# STM32C591xx register map
File version: 1.0
Registers are 32-bit, read-write, reset 0x0 unless marked. A register's access mark holds for its fields unless they carry their own. Offsets are from the block's base; [hi:lo] are bit positions; {n}, {i} and the like mark numbered series.

## TIM2 — TIM Address block
Base 0x40000000
Same registers: TIM3 0x40000400, TIM4 0x40000800, TIM5 0x40000C00
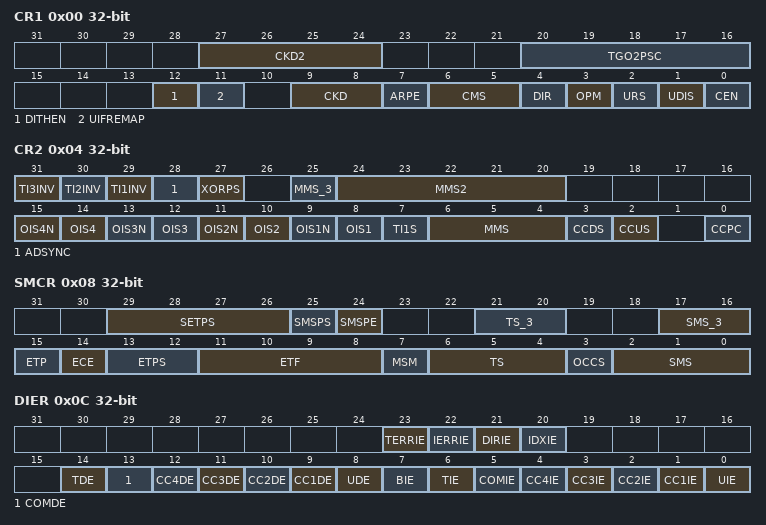
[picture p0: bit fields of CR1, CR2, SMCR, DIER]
0x00 CR1 — TIM control register 1
  [27:24] CKD2 — CKD2[3:0] bits (Clock division 2)
  [20:16] TGO2PSC — TGO2PSC[4:0] bits (Trigger output 2 postscaler)
  [12] DITHEN — DITHEN (Dithering enable)
  [11] UIFREMAP — UIFREMAP (UIF status bit remapping)
  [9:8] CKD — CKD[1:0] bits (Clock division)
  [7] ARPE — ARPE (Auto-reload preload enable)
  [6:5] CMS — CMS[1:0] bits (Center-aligned mode selection)
  [4] DIR — DIR (Direction)
  [3] OPM — OPM (One-pulse mode)
  [2] URS — URS (Update request source)
  [1] UDIS — UDIS (Update disable)
  [0] CEN — CEN (Counter enable)
0x04 CR2 — TIM control register 2
  [31] TI3INV — TI3INV (tim_ti{1} signal inversion on XOR gate input)
  [30] TI2INV — TI2INV (tim_ti{1} signal inversion on XOR gate input)
  [29] TI1INV — TI1INV (tim_ti{1} signal inversion on XOR gate input)
  [28] ADSYNC — ADSYNC (ADC synchronization)
  [27] XORPS — XORPS (XOR gate position selection)
  [25] MMS_3 — MMS[2:0] bits (Master mode selection)
  [24:20] MMS2 — MMS2[4:0] bits (Master mode selection 2)
  [2n+7] OIS{n}N (n=1..4) — OIS{n}N (Output idle state {n} (tim_oc{n}n output))
  [2n+6] OIS{n} (n=1..4) — OIS{n} (Output idle state {n} (tim_oc{n} output))
  [7] TI1S — TI1S (tim_ti1 selection)
  [6:4] MMS — MMS[2:0] bits (Master mode selection)
  [3] CCDS — CCDS (Capture/compare DMA selection)
  [2] CCUS — CCUS (Capture/compare control update selection)
  [0] CCPC — CCPC (Capture/compare preloaded control)
0x08 SMCR — TIM slave mode control register
  [29:26] SETPS — SETPS[3:0] bits (Synchronous External Trigger Prescaler)
  [25] SMSPS — SMSPS (SMS preload source)
  [24] SMSPE — SMSPE (SMS preload enable)
  [21:20] TS_3 — TS[2:0] bits (Trigger selection)
  [17:16] SMS_3 — SMS[2:0] bits (Slave mode selection)
  [15] ETP — ETP (External trigger polarity)
  [14] ECE — ECE (External clock enable)
  [13:12] ETPS — ETPS[1:0] bits (External trigger prescaler)
  [11:8] ETF — ETF[3:0] bits (External trigger filter)
  [7] MSM — MSM (Master/slave mode)
  [6:4] TS — TS[2:0] bits (Trigger selection)
  [3] OCCS — OCCS (OCREF clear selection)
  [2:0] SMS — SMS[2:0] bits (Slave mode selection)
0x0C DIER — TIM DMA/interrupt enable register
  [23] TERRIE — TERRIE (Transition error interrupt enable)
  [22] IERRIE — IERRIE (Index error interrupt enable)
  [21] DIRIE — DIRIE (Direction change interrupt enable)
  [20] IDXIE — IDXIE (Index interrupt enable)
  [14] TDE — TDE (Trigger DMA request enable)
  [13] COMDE — COMDE (COM DMA request enable)
  [n+8] CC{n}DE (n=1..4) — CC{n}DE (Capture/compare {n} DMA request enable)
  [8] UDE — UDE (Update DMA request enable)
  [7] BIE — BIE (Break interrupt enable)
  [6] TIE — TIE (Trigger interrupt enable)
  [5] COMIE — COMIE (COM interrupt enable)
  [n] CC{n}IE (n=1..4) — CC{n}IE (Capture/compare {n} interrupt enable)
  [0] UIE — UIE (Update interrupt enable)
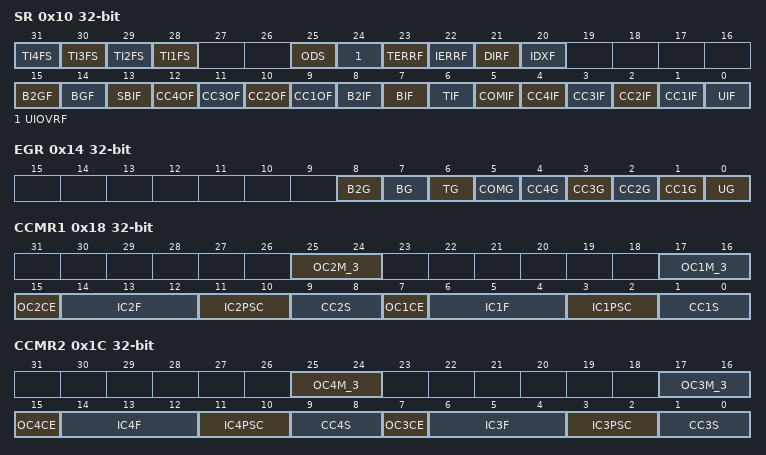
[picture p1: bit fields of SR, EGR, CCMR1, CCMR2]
0x10 SR — TIM status register
  [n+27] TI{n}FS (n=1..4) — TI{n}FS (tim_in{n}f status)
  [25] ODS — ODS (Output disable status)
  [24] UIOVRF — UIOVRF (Update Interrupt Overrun flag)
  [23] TERRF — TERRF (Transition error interrupt flag)
  [22] IERRF — IERRF (Index error interrupt flag)
  [21] DIRF — DIRF (Direction change interrupt flag)
  [20] IDXF — IDXF (Index interrupt flag)
  [15] B2GF — B2GF (Break 2 generation flag)
  [14] BGF — BGF (Break generation flag)
  [13] SBIF — SBIF (System break interrupt flag)
  [n+8] CC{n}OF (n=1..4) — CC{n}OF (Capture/compare {n} overcapture flag)
  [8] B2IF — B2IF (Break 2 interrupt flag)
  [7] BIF — BIF (Break interrupt flag)
  [6] TIF — TIF (Trigger interrupt flag)
  [5] COMIF — COMIF (COM interrupt flag)
  [n] CC{n}IF (n=1..4) — CC{n}IF (Capture/compare {n} interrupt flag)
  [0] UIF — UIF (Update interrupt flag)
0x14 EGR — TIM event generation register
  [8] B2G — B2G (Break 2 generation)
  [7] BG — BG (Break generation)
  [6] TG — TG (Trigger generation)
  [5] COMG — COMG (Capture/compare control update generation)
  [n] CC{n}G (n=1..4) — CC{n}G (Capture/compare {n} generation)
  [0] UG — UG (Update generation)
0x18 CCMR1 — TIM capture/compare mode register 1 [alternate]
  [25:24] OC2M_3 — OC2M[2:0] bits (Output compare 2 mode)
  [17:16] OC1M_3 — OC1M[2:0] bits (Output compare 1 mode)
  [15] OC2CE — OC2CE (Output compare 2 clear enable)
  [14:12] IC2F — IC2F[3:0] bits (Input capture 2 filter)
  [11:10] IC2PSC — IC2PSC[1:0] bits (Input capture 2 prescaler)
  [9:8] CC2S — CC2S[1:0] bits (Capture/compare 2 selection)
  [7] OC1CE — OC1CE (Output compare 1 clear enable)
  [6:4] IC1F — IC1F[3:0] bits (Input capture 1 filter)
  [3:2] IC1PSC — IC1PSC[1:0] bits (Input capture 1 prescaler)
  [1:0] CC1S — CC1S[1:0] bits (Capture/compare 1 selection)
0x1C CCMR2 — TIM capture/compare mode register 2 [alternate]
  [25:24] OC4M_3 — OC4M[2:0] bits (Output compare 4 mode)
  [17:16] OC3M_3 — OC3M[2:0] bits (Output compare 3 mode)
  [15] OC4CE — OC4CE (Output compare 4 clear enable)
  [14:12] IC4F — IC4F[3:0] bits (Input capture 4 filter)
  [11:10] IC4PSC — IC4PSC[1:0] bits (Input capture 4 prescaler)
  [9:8] CC4S — CC4S[1:0] bits (Capture/compare 4 selection)
  [7] OC3CE — OC3CE (Output compare 3 clear enable)
  [6:4] IC3F — IC3F[3:0] bits (Input capture 3 filter)
  [3:2] IC3PSC — IC3PSC[1:0] bits (Input capture 3 prescaler)
  [1:0] CC3S — CC3S[1:0] bits (Capture/compare 3 selection)
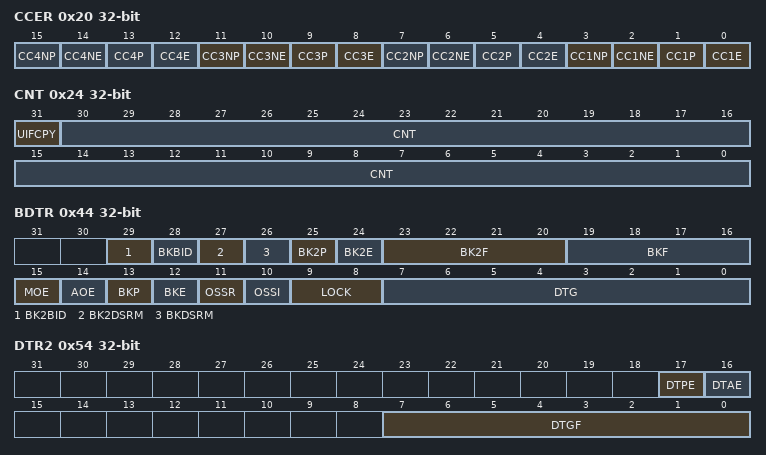
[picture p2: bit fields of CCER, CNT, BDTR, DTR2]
0x20 CCER — TIM capture/compare enable register
  [4n-1] CC{n}NP (n=1..4) — CC{n}NP (Capture/compare {n} complementary output polarity)
  [4n-2] CC{n}NE (n=1..4) — CC{n}NE (Capture/compare {n} complementary output enable)
  [4n-3] CC{n}P (n=1..4) — CC{n}P (Capture/compare {n} output polarity)
  [4n-4] CC{n}E (n=1..4) — CC{n}E (Capture/compare {n} output enable)
0x24 CNT — TIM counter
  [31] UIFCPY — UIFCPY (UIF copy)
  [30:0] CNT — CNT[30:0] bits (Counter value)
0x28 PSC — TIM prescaler
  [15:0] PSC — PSC[15:0] bits (Prescaler value)
0x2C ARR — TIM autoreload register
  [31:0] ARR — ARR[31:0] bits (Auto-reload value)
0x30 RCR — TIM repetition counter register
  [15:0] REP — REP[15:0] bits (Repetition counter reload value)
{0x30+4i} CCR{i} (i=1..3) — TIM capture/compare register {i}
  [31:0] CCR{i} — CCR{i}[31:0] bits (Capture/compare {i} value)
0x40 CCR4 — TIM capture/compare register 4
  [31:0] CCR4 — CCR4[19:0] bits (Capture/compare 4 value)
0x44 BDTR — TIM break and dead-time register
  [29] BK2BID — BK2BID (Break2 bidirectional)
  [28] BKBID — BKBID (Break bidirectional)
  [27] BK2DSRM — BK2DSRM (Break2 disarm)
  [26] BKDSRM — BKDSRM (Break disarm)
  [25] BK2P — BK2P (Break 2 polarity)
  [24] BK2E — BK2E (Break 2 enable)
  [23:20] BK2F — BK2F[3:0] bits (Break 2 filter)
  [19:16] BKF — BKF[3:0] bits (Break filter)
  [15] MOE — MOE (Main output enable)
  [14] AOE — AOE (Automatic output enable)
  [13] BKP — BKP (Break polarity)
  [12] BKE — BKE (Break enable)
  [11] OSSR — OSSR (Off-state selection for Run mode)
  [10] OSSI — OSSI (Off-state selection for idle mode)
  [9:8] LOCK — LOCK[1:0] bits (Lock configuration)
  [7:0] DTG — DTG[7:0] bits (Dead-time generator setup)
0x54 DTR2 — TIM timer deadtime register 2
  [17] DTPE — DTPE (Deadtime preload enable)
  [16] DTAE — DTAE (Deadtime asymmetric enable)
  [7:0] DTGF — DTGF[7:0] bits (Dead-time falling edge generator setup)
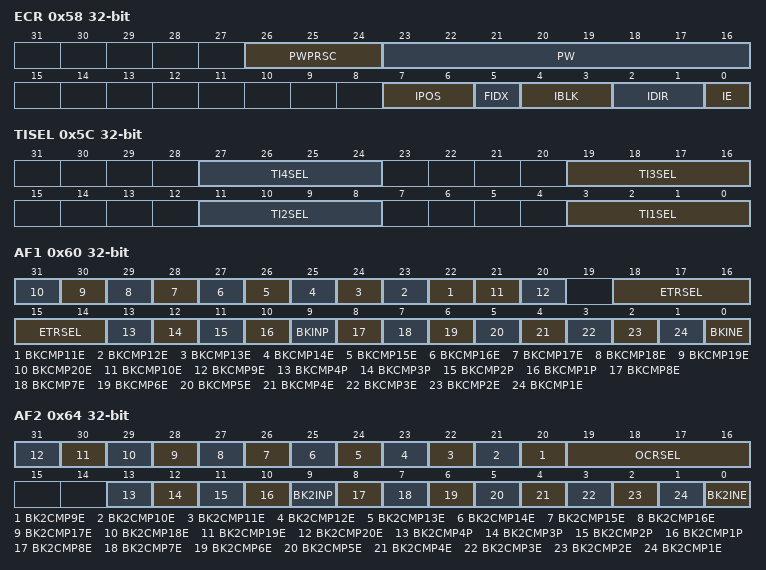
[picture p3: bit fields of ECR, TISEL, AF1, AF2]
0x58 ECR — TIM timer encoder control register
  [26:24] PWPRSC — PWPRSC[2:0] bits (Pulse width prescaler)
  [23:16] PW — PW[7:0] bits (Pulse width)
  [7:6] IPOS — IPOS[1:0] bits (Index positioning)
  [5] FIDX — FIDX (First index)
  [4:3] IBLK — IBLK[1:0] bits (Index blanking)
  [2:1] IDIR — IDIR[1:0] bits (Index direction)
  [0] IE — IE (Index enable)
0x5C TISEL — TIM timer input selection register
  [8n-5:8n-8] TI{n}SEL (n=1..4) — TI{n}SEL[3:0] bits (Selects tim_ti{n}[0..15] input)
0x60 AF1 — TIM alternate function option register 1
  [n+11] BKCMP{n}E (n=11..20) — tim_brk_cmp{n} enable
  [21] BKCMP10E — BKCMP10E (tim_brk_cmp10 enable)
  [20] BKCMP9E — BKCMP9E (tim_brk_cmp9 enable)
  [18:14] ETRSEL — ETRSEL[4:0] bits (etr_in source selection)
  [13] BKCMP4P — tim_brk_cmp4 input polarity
  [12] BKCMP3P — tim_brk_cmp3 input polarity
  [11] BKCMP2P — tim_brk_cmp2 input polarity
  [10] BKCMP1P — BKCMP1P (tim_brk_cmp1 input polarity)
  [9] BKINP — BKINP (TIMx_BKIN input polarity)
  [8] BKCMP8E — BKCMP8E (tim_brk_cmp8 enable)
  [7] BKCMP7E — tim_brk_cmp7 enable
  [6] BKCMP6E — BKCMP6E (tim_brk_cmp6 enable)
  [5] BKCMP5E — BKCMP5E (tim_brk_cmp5 enable)
  [4] BKCMP4E — tim_brk_cmp4 enable
  [3] BKCMP3E — tim_brk_cmp3 enable
  [2] BKCMP2E — tim_brk_cmp2 enable
  [1] BKCMP1E — BKCMP1E (tim_brk_cmp1 enable)
  [0] BKINE — BKINE (TIMx_BKIN input enable)
0x64 AF2 — TIM alternate function register 2
  [n+11] BK2CMP{n}E (n=9..20) — tim_brk2_cmp{n} enable
  [19:16] OCRSEL — OCRSEL[3:0] bits (ocref_clr source selection)
  [13] BK2CMP4P — tim_brk2_cmp4 input polarity
  [12] BK2CMP3P — tim_brk2_cmp3 input polarity
  [11] BK2CMP2P — tim_brk2_cmp2 input polarity
  [10] BK2CMP1P — BK2CMP1P (tim_brk2_cmp1 input polarity)
  [9] BK2INP — BK2INP (TIMx_BKIN2 input polarity)
  [8] BK2CMP8E — tim_brk2_cmp8 enable
  [7] BK2CMP7E — tim_brk2_cmp7 enable
  [6] BK2CMP6E — BK2CMP6E (tim_brk2_cmp8 enable)
  [5] BK2CMP5E — BK2CMP5E (tim_brk2_cmp8 enable)
  [4] BK2CMP4E — tim_brk2_cmp4 enable
  [3] BK2CMP3E — tim_brk2_cmp3 enable
  [2] BK2CMP2E — tim_brk2_cmp2 enable
  [1] BK2CMP1E — BK2CMP1E (tim_brk2_cmp8 enable)
  [0] BK2INE — BK2INE (TIMx_BKIN2 input enable)
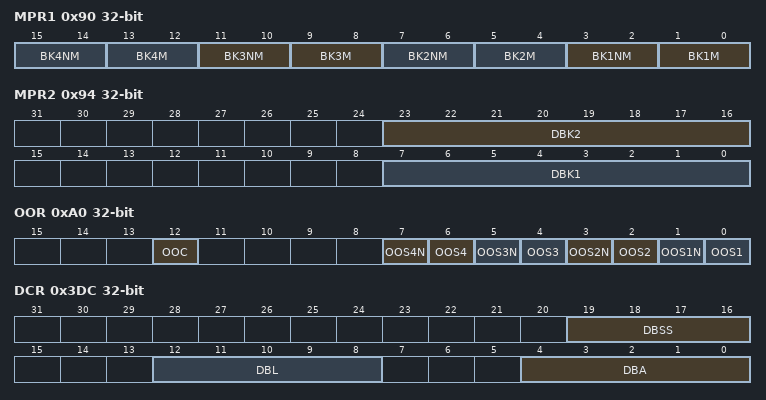
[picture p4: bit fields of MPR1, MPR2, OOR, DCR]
0x90 MPR1 — TIM multilevel protection register 1
  [4n-1:4n-2] BK{n}NM (n=1..4) — BK{n}NM[1:0] bits (Break mode for tim_oc{n}n output)
  [4n-3:4n-4] BK{n}M (n=1..4) — BK{n}M[1:0] bits (Break mode for tim_oc{n} output)
0x94 MPR2 — TIM multilevel protection register 2
  [23:16] DBK2 — DBK2[7:0] bits (Delayed 2 Break duration)
  [7:0] DBK1 — DBK1[7:0] bits (Delayed 1 Break duration)
0xA0 OOR — TIM output override register
  [12] OOC — OOC (Output override control)
  [2n-1] OOS{n}N (n=1..4) — OOS{n}N (Output override state for output tim_oc{n}n)
  [2n-2] OOS{n} (n=1..4) — OOS{n} (Output override state for output tim_oc{n}n)
0x3DC DCR — TIM DMA control register
  [19:16] DBSS — DBSS[3:0] bits (DMA burst source selection)
  [12:8] DBL — DBL[4:0] bits (DMA burst length)
  [4:0] DBA — DBA[4:0] bits (DMA base address)
0x3E0 DMAR — TIM DMA address for full transfer
  [31:0] DMAB — DMAB[31:0] bits (DMA register for burst accesses)

## TIM6 — TIM Address block
Base 0x40001000
Same registers: TIM7 0x40001400
Registers as TIM2, without CCMR1, CCMR2, CCER, CCR{n} (n=1..4); these are added or differ:
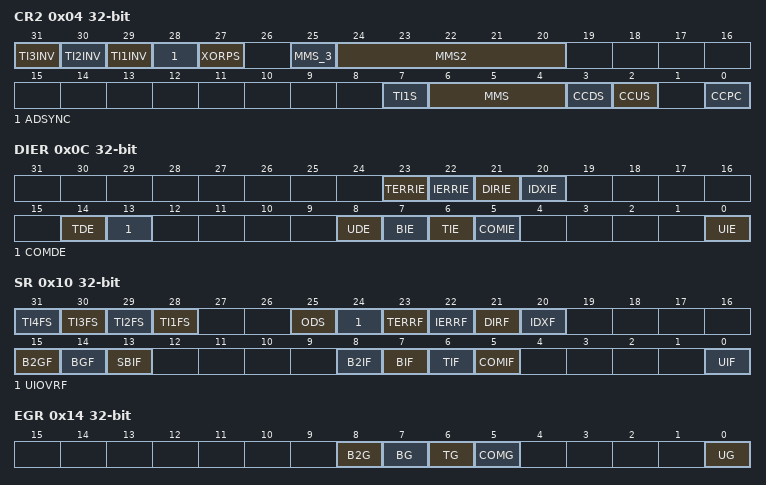
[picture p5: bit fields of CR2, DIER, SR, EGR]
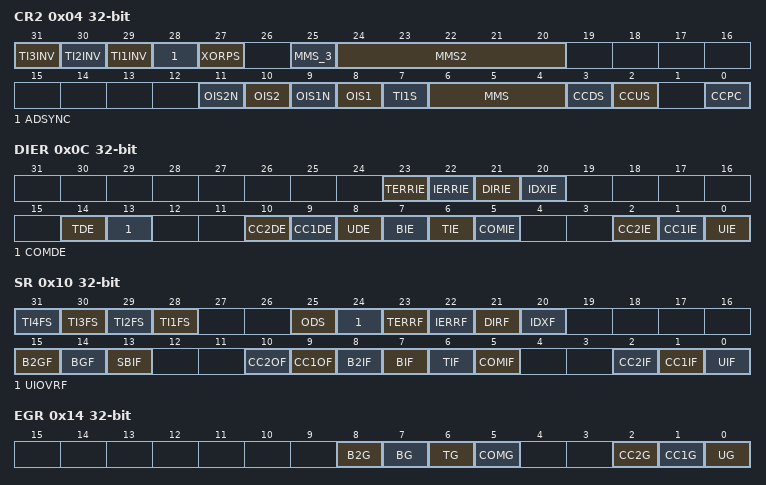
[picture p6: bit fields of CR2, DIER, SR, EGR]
0x04 CR2 — TIM control register 2
  [31] TI3INV — TI3INV (tim_ti{1} signal inversion on XOR gate input)
  [30] TI2INV — TI2INV (tim_ti{1} signal inversion on XOR gate input)
  [29] TI1INV — TI1INV (tim_ti{1} signal inversion on XOR gate input)
  [28] ADSYNC — ADSYNC (ADC synchronization)
  [27] XORPS — XORPS (XOR gate position selection)
  [25] MMS_3 — MMS[2:0] bits (Master mode selection)
  [24:20] MMS2 — MMS2[4:0] bits (Master mode selection 2)
  [7] TI1S — TI1S (tim_ti1 selection)
  [6:4] MMS — MMS[2:0] bits (Master mode selection)
  [3] CCDS — CCDS (Capture/compare DMA selection)
  [2] CCUS — CCUS (Capture/compare control update selection)
  [0] CCPC — CCPC (Capture/compare preloaded control)
0x0C DIER — TIM DMA/interrupt enable register
  [23] TERRIE — TERRIE (Transition error interrupt enable)
  [22] IERRIE — IERRIE (Index error interrupt enable)
  [21] DIRIE — DIRIE (Direction change interrupt enable)
  [20] IDXIE — IDXIE (Index interrupt enable)
  [14] TDE — TDE (Trigger DMA request enable)
  [13] COMDE — COMDE (COM DMA request enable)
  [8] UDE — UDE (Update DMA request enable)
  [7] BIE — BIE (Break interrupt enable)
  [6] TIE — TIE (Trigger interrupt enable)
  [5] COMIE — COMIE (COM interrupt enable)
  [0] UIE — UIE (Update interrupt enable)
0x10 SR — TIM status register
  [n+27] TI{n}FS (n=1..4) — TI{n}FS (tim_in{n}f status)
  [25] ODS — ODS (Output disable status)
  [24] UIOVRF — UIOVRF (Update Interrupt Overrun flag)
  [23] TERRF — TERRF (Transition error interrupt flag)
  [22] IERRF — IERRF (Index error interrupt flag)
  [21] DIRF — DIRF (Direction change interrupt flag)
  [20] IDXF — IDXF (Index interrupt flag)
  [15] B2GF — B2GF (Break 2 generation flag)
  [14] BGF — BGF (Break generation flag)
  [13] SBIF — SBIF (System break interrupt flag)
  [8] B2IF — B2IF (Break 2 interrupt flag)
  [7] BIF — BIF (Break interrupt flag)
  [6] TIF — TIF (Trigger interrupt flag)
  [5] COMIF — COMIF (COM interrupt flag)
  [0] UIF — UIF (Update interrupt flag)
0x14 EGR — TIM event generation register
  [8] B2G — B2G (Break 2 generation)
  [7] BG — BG (Break generation)
  [6] TG — TG (Trigger generation)
  [5] COMG — COMG (Capture/compare control update generation)
  [0] UG — UG (Update generation)

## TIM12 — TIM Address block
Base 0x40001800
Same registers: TIM15 0x40014000
Registers as TIM2, without CCMR2, CCR3, CCR4; these are added or differ:
0x04 CR2 — TIM control register 2
  [31] TI3INV — TI3INV (tim_ti{1} signal inversion on XOR gate input)
  [30] TI2INV — TI2INV (tim_ti{1} signal inversion on XOR gate input)
  [29] TI1INV — TI1INV (tim_ti{1} signal inversion on XOR gate input)
  [28] ADSYNC — ADSYNC (ADC synchronization)
  [27] XORPS — XORPS (XOR gate position selection)
  [25] MMS_3 — MMS[2:0] bits (Master mode selection)
  [24:20] MMS2 — MMS2[4:0] bits (Master mode selection 2)
  [11] OIS2N — OIS2N (Output idle state 2 (tim_oc2n output))
  [10] OIS2 — OIS2 (Output idle state 2 (tim_oc2 output))
  [9] OIS1N — OIS1N (Output idle state 1 (tim_oc1n output))
  [8] OIS1 — OIS1 (Output idle state 1 (tim_oc1 output))
  [7] TI1S — TI1S (tim_ti1 selection)
  [6:4] MMS — MMS[2:0] bits (Master mode selection)
  [3] CCDS — CCDS (Capture/compare DMA selection)
  [2] CCUS — CCUS (Capture/compare control update selection)
  [0] CCPC — CCPC (Capture/compare preloaded control)
0x0C DIER — TIM DMA/interrupt enable register
  [23] TERRIE — TERRIE (Transition error interrupt enable)
  [22] IERRIE — IERRIE (Index error interrupt enable)
  [21] DIRIE — DIRIE (Direction change interrupt enable)
  [20] IDXIE — IDXIE (Index interrupt enable)
  [14] TDE — TDE (Trigger DMA request enable)
  [13] COMDE — COMDE (COM DMA request enable)
  [10] CC2DE — CC2DE (Capture/compare 2 DMA request enable)
  [9] CC1DE — CC1DE (Capture/compare 1 DMA request enable)
  [8] UDE — UDE (Update DMA request enable)
  [7] BIE — BIE (Break interrupt enable)
  [6] TIE — TIE (Trigger interrupt enable)
  [5] COMIE — COMIE (COM interrupt enable)
  [2] CC2IE — CC2IE (Capture/compare 2 interrupt enable)
  [1] CC1IE — CC1IE (Capture/compare 1 interrupt enable)
  [0] UIE — UIE (Update interrupt enable)
0x10 SR — TIM status register
  [n+27] TI{n}FS (n=1..4) — TI{n}FS (tim_in{n}f status)
  [25] ODS — ODS (Output disable status)
  [24] UIOVRF — UIOVRF (Update Interrupt Overrun flag)
  [23] TERRF — TERRF (Transition error interrupt flag)
  [22] IERRF — IERRF (Index error interrupt flag)
  [21] DIRF — DIRF (Direction change interrupt flag)
  [20] IDXF — IDXF (Index interrupt flag)
  [15] B2GF — B2GF (Break 2 generation flag)
  [14] BGF — BGF (Break generation flag)
  [13] SBIF — SBIF (System break interrupt flag)
  [10] CC2OF — CC2OF (Capture/compare 2 overcapture flag)
  [9] CC1OF — CC1OF (Capture/compare 1 overcapture flag)
  [8] B2IF — B2IF (Break 2 interrupt flag)
  [7] BIF — BIF (Break interrupt flag)
  [6] TIF — TIF (Trigger interrupt flag)
  [5] COMIF — COMIF (COM interrupt flag)
  [2] CC2IF — CC2IF (Capture/compare 2 interrupt flag)
  [1] CC1IF — CC1IF (Capture/compare 1 interrupt flag)
  [0] UIF — UIF (Update interrupt flag)
0x14 EGR — TIM event generation register
  [8] B2G — B2G (Break 2 generation)
  [7] BG — BG (Break generation)
  [6] TG — TG (Trigger generation)
  [5] COMG — COMG (Capture/compare control update generation)
  [2] CC2G — CC2G (Capture/compare 2 generation)
  [1] CC1G — CC1G (Capture/compare 1 generation)
  [0] UG — UG (Update generation)
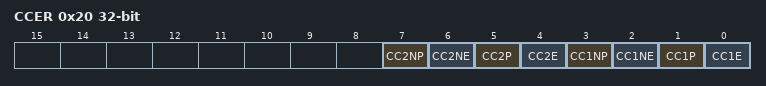
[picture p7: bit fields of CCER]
0x20 CCER — TIM capture/compare enable register
  [7] CC2NP — CC2NP (Capture/compare 2 complementary output polarity)
  [6] CC2NE — CC2NE (Capture/compare 2 complementary output enable)
  [5] CC2P — CC2P (Capture/compare 2 output polarity)
  [4] CC2E — CC2E (Capture/compare 2 output enable)
  [3] CC1NP — CC1NP (Capture/compare 1 complementary output polarity)
  [2] CC1NE — CC1NE (Capture/compare 1 complementary output enable)
  [1] CC1P — CC1P (Capture/compare 1 output polarity)
  [0] CC1E — CC1E (Capture/compare 1 output enable)

## TIM1 — TIM Address block
Base 0x40012C00
Same registers: TIM8 0x40013400
Registers as TIM2; these are added or differ:
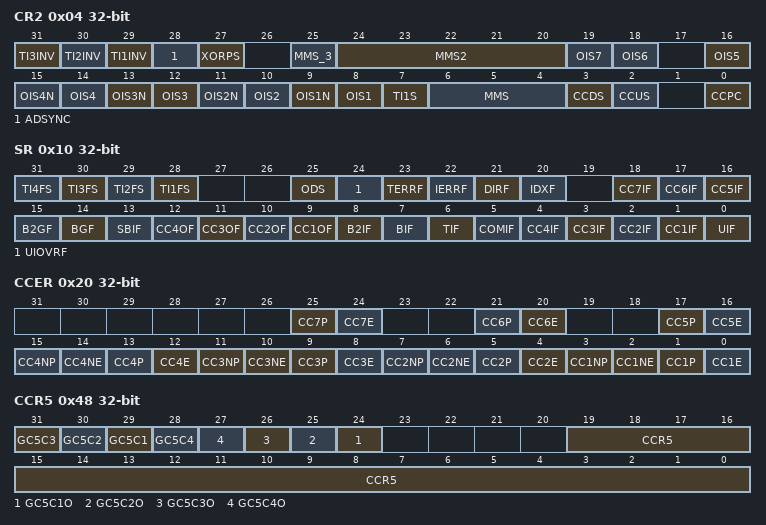
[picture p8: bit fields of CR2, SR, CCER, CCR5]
0x04 CR2 — TIM control register 2
  [31] TI3INV — TI3INV (tim_ti{1} signal inversion on XOR gate input)
  [30] TI2INV — TI2INV (tim_ti{1} signal inversion on XOR gate input)
  [29] TI1INV — TI1INV (tim_ti{1} signal inversion on XOR gate input)
  [28] ADSYNC — ADSYNC (ADC synchronization)
  [27] XORPS — XORPS (XOR gate position selection)
  [25] MMS_3 — MMS[2:0] bits (Master mode selection)
  [24:20] MMS2 — MMS2[4:0] bits (Master mode selection 2)
  [19] OIS7 — OIS7 (Output idle state 7 (tim_oc7 output))
  [2n+6] OIS{n} (n=1..6) — OIS{n} (Output idle state {n} (tim_oc{n} output))
  [2n+7] OIS{n}N (n=1..4) — OIS{n}N (Output idle state {n} (tim_oc{n}n output))
  [7] TI1S — TI1S (tim_ti1 selection)
  [6:4] MMS — MMS[2:0] bits (Master mode selection)
  [3] CCDS — CCDS (Capture/compare DMA selection)
  [2] CCUS — CCUS (Capture/compare control update selection)
  [0] CCPC — CCPC (Capture/compare preloaded control)
0x10 SR — TIM status register
  [n+27] TI{n}FS (n=1..4) — TI{n}FS (tim_in{n}f status)
  [25] ODS — ODS (Output disable status)
  [24] UIOVRF — UIOVRF (Update Interrupt Overrun flag)
  [23] TERRF — TERRF (Transition error interrupt flag)
  [22] IERRF — IERRF (Index error interrupt flag)
  [21] DIRF — DIRF (Direction change interrupt flag)
  [20] IDXF — IDXF (Index interrupt flag)
  [18] CC7IF — CC7IF (Compare 7 interrupt flag)
  [17] CC6IF — CC6IF (Compare 6 interrupt flag)
  [16] CC5IF — CC5IF (Compare 5 interrupt flag)
  [15] B2GF — B2GF (Break 2 generation flag)
  [14] BGF — BGF (Break generation flag)
  [13] SBIF — SBIF (System break interrupt flag)
  [n+8] CC{n}OF (n=1..4) — CC{n}OF (Capture/compare {n} overcapture flag)
  [8] B2IF — B2IF (Break 2 interrupt flag)
  [7] BIF — BIF (Break interrupt flag)
  [6] TIF — TIF (Trigger interrupt flag)
  [5] COMIF — COMIF (COM interrupt flag)
  [n] CC{n}IF (n=1..4) — CC{n}IF (Capture/compare {n} interrupt flag)
  [0] UIF — UIF (Update interrupt flag)
0x20 CCER — TIM capture/compare enable register
  [4n-3] CC{n}P (n=1..7) — CC{n}P (Capture/compare {n} output polarity)
  [4n-4] CC{n}E (n=1..7) — CC{n}E (Capture/compare {n} output enable)
  [4n-1] CC{n}NP (n=1..4) — CC{n}NP (Capture/compare {n} complementary output polarity)
  [4n-2] CC{n}NE (n=1..4) — CC{n}NE (Capture/compare {n} complementary output enable)
0x48 CCR5 — TIM capture/compare register 5
  [31] GC5C3 — GC5C3 (Group channel 5 and channel 3)
  [30] GC5C2 — GC5C2 (Group channel 5 and channel 2)
  [29] GC5C1 — GC5C1 (Group channel 5 and channel 1)
  [28] GC5C4 — GC5C4 (Group channel 5 and channel 4)
  [n+23] GC5C{n}O (n=1..4) — GC5C{n}O (Group channel 5 and channel {n} (ORed))
  [19:0] CCR5 — CCR5[19:0] bits (Capture/compare 5 value)
0x4C CCR6 — TIM capture/compare register 6
  [19:0] CCR6 — CCR6[19:0] bits (Capture/compare 6 value)
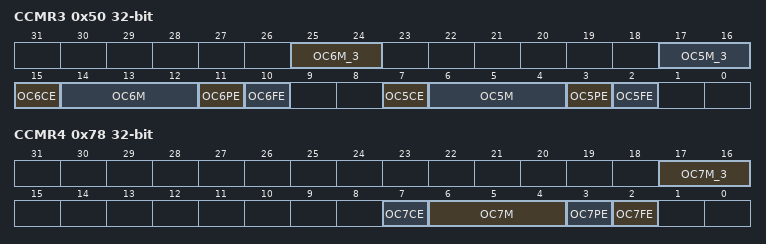
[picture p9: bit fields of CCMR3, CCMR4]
0x50 CCMR3 — TIM capture/compare mode register 3
  [25:24] OC6M_3 — OC6M[2:0] bits (Output compare 6 mode)
  [17:16] OC5M_3 — OC5M[2:0] bits (Output compare 5 mode)
  [15] OC6CE — OC6CE (Output compare 6 clear enable)
  [14:12] OC6M — OC6M[2:0] bits (Output compare 6 mode)
  [11] OC6PE — OC6PE (Output compare 6 preload enable)
  [10] OC6FE — OC6FE (Output compare 6 fast enable)
  [7] OC5CE — OC5CE (Output compare 5 clear enable)
  [6:4] OC5M — OC5M[2:0] bits (Output compare 5 mode)
  [3] OC5PE — OC5PE (Output compare 5 preload enable)
  [2] OC5FE — OC5FE (Output compare 5 fast enable)
0x70 CCR7 — TIM capture/compare register 7
  [19:0] CCR7 — CCR7[19:0] bits (Capture/compare 7 value)
0x78 CCMR4 — TIM capture/compare mode register 4
  [17:16] OC7M_3 — OC7M[2:0] bits (Output compare 7 mode)
  [7] OC7CE — OC7CE (Output compare 7 clear enable)
  [6:4] OC7M — OC7M[2:0] bits (Output compare 7 mode)
  [3] OC7PE — OC7PE (Output compare 7 preload enable)
  [2] OC7FE — OC7FE (Output compare 7 fast enable)

## TIM16 — TIM Address block
Base 0x40014400
Same registers: TIM17 0x40014800
Registers as TIM2, without CCMR2, CCR{n} (n=2..4); these are added or differ:
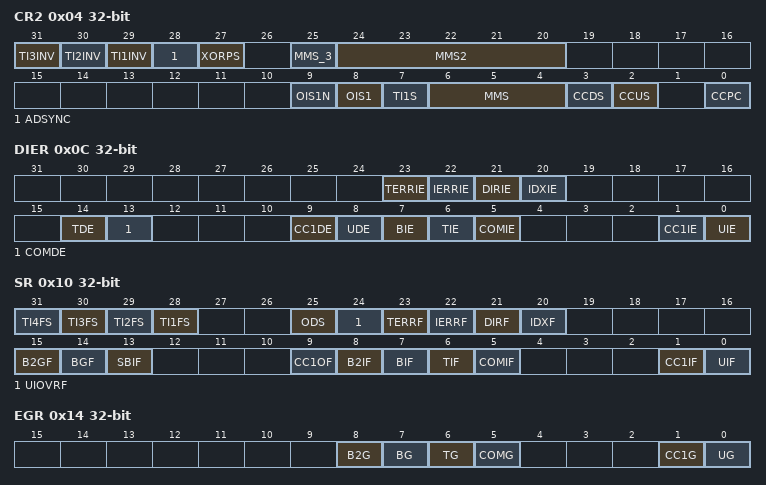
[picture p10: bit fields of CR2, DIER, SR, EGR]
0x04 CR2 — TIM control register 2
  [31] TI3INV — TI3INV (tim_ti{1} signal inversion on XOR gate input)
  [30] TI2INV — TI2INV (tim_ti{1} signal inversion on XOR gate input)
  [29] TI1INV — TI1INV (tim_ti{1} signal inversion on XOR gate input)
  [28] ADSYNC — ADSYNC (ADC synchronization)
  [27] XORPS — XORPS (XOR gate position selection)
  [25] MMS_3 — MMS[2:0] bits (Master mode selection)
  [24:20] MMS2 — MMS2[4:0] bits (Master mode selection 2)
  [9] OIS1N — OIS1N (Output idle state 1 (tim_oc1n output))
  [8] OIS1 — OIS1 (Output idle state 1 (tim_oc1 output))
  [7] TI1S — TI1S (tim_ti1 selection)
  [6:4] MMS — MMS[2:0] bits (Master mode selection)
  [3] CCDS — CCDS (Capture/compare DMA selection)
  [2] CCUS — CCUS (Capture/compare control update selection)
  [0] CCPC — CCPC (Capture/compare preloaded control)
0x0C DIER — TIM DMA/interrupt enable register
  [23] TERRIE — TERRIE (Transition error interrupt enable)
  [22] IERRIE — IERRIE (Index error interrupt enable)
  [21] DIRIE — DIRIE (Direction change interrupt enable)
  [20] IDXIE — IDXIE (Index interrupt enable)
  [14] TDE — TDE (Trigger DMA request enable)
  [13] COMDE — COMDE (COM DMA request enable)
  [9] CC1DE — CC1DE (Capture/compare 1 DMA request enable)
  [8] UDE — UDE (Update DMA request enable)
  [7] BIE — BIE (Break interrupt enable)
  [6] TIE — TIE (Trigger interrupt enable)
  [5] COMIE — COMIE (COM interrupt enable)
  [1] CC1IE — CC1IE (Capture/compare 1 interrupt enable)
  [0] UIE — UIE (Update interrupt enable)
0x10 SR — TIM status register
  [n+27] TI{n}FS (n=1..4) — TI{n}FS (tim_in{n}f status)
  [25] ODS — ODS (Output disable status)
  [24] UIOVRF — UIOVRF (Update Interrupt Overrun flag)
  [23] TERRF — TERRF (Transition error interrupt flag)
  [22] IERRF — IERRF (Index error interrupt flag)
  [21] DIRF — DIRF (Direction change interrupt flag)
  [20] IDXF — IDXF (Index interrupt flag)
  [15] B2GF — B2GF (Break 2 generation flag)
  [14] BGF — BGF (Break generation flag)
  [13] SBIF — SBIF (System break interrupt flag)
  [9] CC1OF — CC1OF (Capture/compare 1 overcapture flag)
  [8] B2IF — B2IF (Break 2 interrupt flag)
  [7] BIF — BIF (Break interrupt flag)
  [6] TIF — TIF (Trigger interrupt flag)
  [5] COMIF — COMIF (COM interrupt flag)
  [1] CC1IF — CC1IF (Capture/compare 1 interrupt flag)
  [0] UIF — UIF (Update interrupt flag)
0x14 EGR — TIM event generation register
  [8] B2G — B2G (Break 2 generation)
  [7] BG — BG (Break generation)
  [6] TG — TG (Trigger generation)
  [5] COMG — COMG (Capture/compare control update generation)
  [1] CC1G — CC1G (Capture/compare 1 generation)
  [0] UG — UG (Update generation)
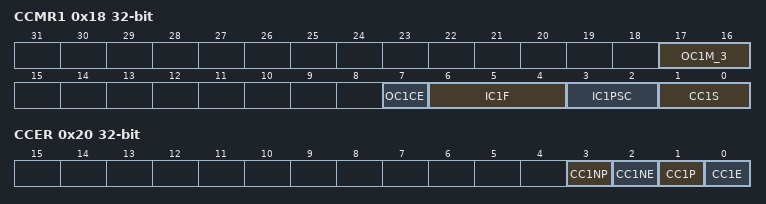
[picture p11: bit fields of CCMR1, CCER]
0x18 CCMR1 — TIM capture/compare mode register 1 [alternate]
  [17:16] OC1M_3 — OC1M[2:0] bits (Output compare 1 mode)
  [7] OC1CE — OC1CE (Output compare 1 clear enable)
  [6:4] IC1F — IC1F[3:0] bits (Input capture 1 filter)
  [3:2] IC1PSC — IC1PSC[1:0] bits (Input capture 1 prescaler)
  [1:0] CC1S — CC1S[1:0] bits (Capture/compare 1 selection)
0x20 CCER — TIM capture/compare enable register
  [3] CC1NP — CC1NP (Capture/compare 1 complementary output polarity)
  [2] CC1NE — CC1NE (Capture/compare 1 complementary output enable)
  [1] CC1P — CC1P (Capture/compare 1 output polarity)
  [0] CC1E — CC1E (Capture/compare 1 output enable)
